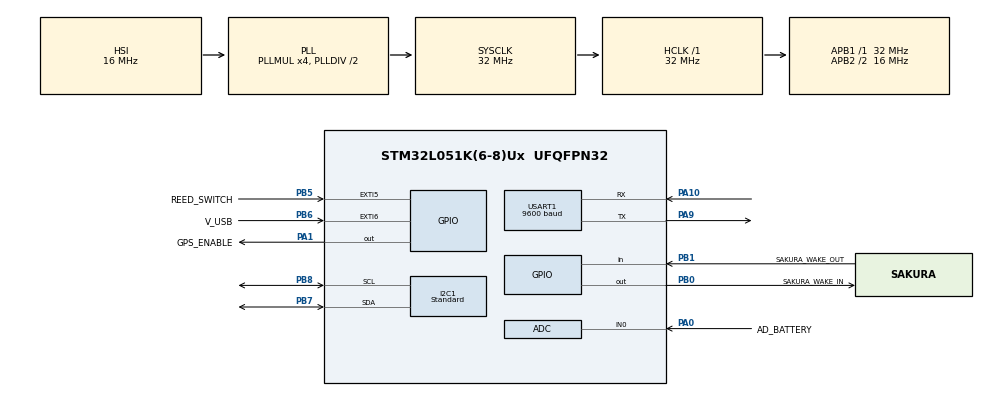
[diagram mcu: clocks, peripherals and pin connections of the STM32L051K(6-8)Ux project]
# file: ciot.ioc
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ADC.ContinuousConvMode=ENABLE
ADC.SamplingTime=ADC_SAMPLETIME_7CYCLES_5
I2C1.Analog_Filter=I2C_ANALOGFILTER_ENABLE
I2C1.I2C_Fall_Time=0
I2C1.I2C_Rise_Time=0
I2C1.I2C_Speed_Mode=I2C_Standard
I2C1.OwnAddress=0x33
I2C1.Speed=100
I2C1.Timing=0x00707CBB
Mcu.Family=STM32L0
Mcu.Name=STM32L051K(6-8)Ux
Mcu.Package=UFQFPN32
NVIC.EXTI4_15_IRQn=true\:0\:0\:false\:false\:true
NVIC.I2C1_IRQn=true\:1\:0\:true\:false\:true
PA0.GPIO_Label=AD_BATTERY
PA0.Mode=IN0
PA0.Signal=ADC_IN0
PA1.GPIO_Label=GPS_ENABLE
PA1.Signal=GPIO_Output
PA10.Mode=Asynchronous
PA10.Signal=USART1_RX
PA13.Mode=Serial_Wire
PA13.Signal=SYS_SWDIO
PA14.Mode=Serial_Wire
PA14.Signal=SYS_SWCLK
PA9.Mode=Asynchronous
PA9.Signal=USART1_TX
PB0.GPIO_Label=SAKURA_WAKE_IN
PB0.Signal=GPIO_Output
PB1.GPIO_Label=SAKURA_WAKE_OUT
PB1.GPIO_PuPd=GPIO_PULLDOWN
PB1.Signal=GPIO_Input
PB5.GPIO_Label=REED_SWITCH
PB5.GPIO_ModeDefaultEXTI=GPIO_MODE_IT_FALLING
PB5.Signal=GPXTI5
PB6.GPIO_Label=V_USB
PB6.GPIO_ModeDefaultEXTI=GPIO_MODE_IT_RISING
PB6.GPIO_PuPd=GPIO_PULLDOWN
PB6.Signal=GPXTI6
PB7.GPIO_FM7=__NULL
PB7.GPIO_PuPdOD=GPIO_NOPULL
PB7.Mode=I2C
PB7.Signal=I2C1_SDA
PB8.GPIO_FM8=__NULL
PB8.GPIO_PuPdOD=GPIO_NOPULL
PB8.Mode=I2C
PB8.Signal=I2C1_SCL
PC14-OSC32_IN.Mode=LSE-External-Oscillator
PC14-OSC32_IN.Signal=RCC_OSC32_IN
PC15-OSC32_OUT.Mode=LSE-External-Oscillator
PC15-OSC32_OUT.Signal=RCC_OSC32_OUT
ProjectManager.HeapSize=0x200
ProjectManager.StackSize=0x400
ProjectManager.TargetToolchain=SW4STM32
RCC.AHBFreq_Value=32000000
RCC.APB1Freq_Value=32000000
RCC.APB1TimFreq_Value=32000000
RCC.APB2CLKDivider=RCC_HCLK_DIV2
RCC.APB2Freq_Value=16000000
RCC.APB2TimFreq_Value=32000000
RCC.HCLKFreq_Value=32000000
RCC.HSI16_VALUE=16000000
RCC.HSI_VALUE=16000000
RCC.LptimClockSelection=RCC_LPTIM1CLKSOURCE_LSE
RCC.MSI_VALUE=2097000
RCC.PLLMUL=RCC_PLLMUL_4
RCC.RTCClockSelectionVirtual=RCC_RTCCLKSOURCE_LSE
RCC.SYSCLKFreq_VALUE=32000000
RCC.SYSCLKSource=RCC_SYSCLKSOURCE_PLLCLK
RCC.VCOOutputFreq_Value=64000000
RCC.VDD_VALUE=1.8
USART1.BaudRate=9600
USART1.VirtualMode-Asynchronous=VM_ASYNC
USART1.WordLength=WORDLENGTH_8B
VP_RTC_VS_RTC_Activate.Mode=RTC_Enabled
board=ciot

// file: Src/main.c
/**
  ******************************************************************************
  * File Name          : main.c
  * Description        : Main program body
  ******************************************************************************
  ** This notice applies to any and all portions of this file
  * that are not between comment pairs USER CODE BEGIN and
  * USER CODE END. Other portions of this file, whether
  * inserted by the user or by software development tools
  * are owned by their respective copyright owners.
  *
  * COPYRIGHT(c) 2017 STMicroelectronics
  *
  * Redistribution and use in source and binary forms, with or without modification,
  * are permitted provided that the following conditions are met:
  *   1. Redistributions of source code must retain the above copyright notice,
  *      this list of conditions and the following disclaimer.
  *   2. Redistributions in binary form must reproduce the above copyright notice,
  *      this list of conditions and the following disclaimer in the documentation
  *      and/or other materials provided with the distribution.
  *   3. Neither the name of STMicroelectronics nor the names of its contributors
  *      may be used to endorse or promote products derived from this software
  *      without specific prior written permission.
  *
  * THIS SOFTWARE IS PROVIDED BY THE COPYRIGHT HOLDERS AND CONTRIBUTORS "AS IS"
  * AND ANY EXPRESS OR IMPLIED WARRANTIES, INCLUDING, BUT NOT LIMITED TO, THE
  * IMPLIED WARRANTIES OF MERCHANTABILITY AND FITNESS FOR A PARTICULAR PURPOSE ARE
  * DISCLAIMED. IN NO EVENT SHALL THE COPYRIGHT HOLDER OR CONTRIBUTORS BE LIABLE
  * FOR ANY DIRECT, INDIRECT, INCIDENTAL, SPECIAL, EXEMPLARY, OR CONSEQUENTIAL
  * DAMAGES (INCLUDING, BUT NOT LIMITED TO, PROCUREMENT OF SUBSTITUTE GOODS OR
  * SERVICES; LOSS OF USE, DATA, OR PROFITS; OR BUSINESS INTERRUPTION) HOWEVER
  * CAUSED AND ON ANY THEORY OF LIABILITY, WHETHER IN CONTRACT, STRICT LIABILITY,
  * OR TORT (INCLUDING NEGLIGENCE OR OTHERWISE) ARISING IN ANY WAY OUT OF THE USE
  * OF THIS SOFTWARE, EVEN IF ADVISED OF THE POSSIBILITY OF SUCH DAMAGE.
  *
  ******************************************************************************
  */
#include "main.h"
#include "stm32l0xx_hal.h"

/* USER CODE BEGIN Includes */
#include "ciot.h"
/* USER CODE END Includes */

ADC_HandleTypeDef hadc;

I2C_HandleTypeDef hi2c1;

RTC_HandleTypeDef hrtc;

UART_HandleTypeDef huart1;

/* USER CODE BEGIN PV */
/* Private variables ---------------------------------------------------------*/

/* USER CODE END PV */

void SystemClock_Config(void);
static void MX_GPIO_Init(void);
static void MX_I2C1_Init(void);
static void MX_USART1_UART_Init(void);
static void MX_RTC_Init(void);
static void MX_ADC_Init(void);

/* USER CODE BEGIN PFP */
/* Private function prototypes -----------------------------------------------*/

/* USER CODE END PFP */

int main(void)
{

  /* MCU Configuration----------------------------------------------------------*/

  /* Reset of all peripherals, Initializes the Flash interface and the Systick. */
  HAL_Init();

  /* USER CODE BEGIN Init */

  /* Enable Power Control clock */
  __HAL_RCC_PWR_CLK_ENABLE();

  /* USER CODE END Init */

  /* Configure the system clock */
  SystemClock_Config();

  /* USER CODE BEGIN SysInit */

  /* Disable Prefetch Buffer */
  __HAL_FLASH_PREFETCH_BUFFER_DISABLE();

  /* Enable Ultra low power mode */
  HAL_PWREx_EnableUltraLowPower();
  /* Enable the fast wake up from Ultra low power mode */
  HAL_PWREx_EnableFastWakeUp();

  /* USER CODE END SysInit */

  /* Initialize all configured peripherals */
  MX_GPIO_Init();
  MX_I2C1_Init();
  MX_USART1_UART_Init();
  MX_RTC_Init();
  MX_ADC_Init();

  /* Infinite loop */
  /* USER CODE BEGIN WHILE */
  while (1)
  {
    ciot_main();
  /* USER CODE END WHILE */

  }

}

/** System Clock Configuration
*/
void SystemClock_Config(void)
{

  RCC_OscInitTypeDef RCC_OscInitStruct;
  RCC_ClkInitTypeDef RCC_ClkInitStruct;
  RCC_PeriphCLKInitTypeDef PeriphClkInit;

    /**Configure the main internal regulator output voltage
    */
  __HAL_PWR_VOLTAGESCALING_CONFIG(PWR_REGULATOR_VOLTAGE_SCALE1);

    /**Configure LSE Drive Capability
    */
  __HAL_RCC_LSEDRIVE_CONFIG(RCC_LSEDRIVE_LOW);

    /**Initializes the CPU, AHB and APB busses clocks
    */
  RCC_OscInitStruct.OscillatorType = RCC_OSCILLATORTYPE_HSI|RCC_OSCILLATORTYPE_LSE;
  RCC_OscInitStruct.LSEState = RCC_LSE_ON;
  RCC_OscInitStruct.HSIState = RCC_HSI_ON;
  RCC_OscInitStruct.HSICalibrationValue = 16;
  RCC_OscInitStruct.PLL.PLLState = RCC_PLL_ON;
  RCC_OscInitStruct.PLL.PLLSource = RCC_PLLSOURCE_HSI;
  RCC_OscInitStruct.PLL.PLLMUL = RCC_PLLMUL_4;
  RCC_OscInitStruct.PLL.PLLDIV = RCC_PLLDIV_2;
  if (HAL_RCC_OscConfig(&RCC_OscInitStruct) != HAL_OK)
  {
    _Error_Handler(__FILE__, __LINE__);
  }

    /**Initializes the CPU, AHB and APB busses clocks
    */
  RCC_ClkInitStruct.ClockType = RCC_CLOCKTYPE_HCLK|RCC_CLOCKTYPE_SYSCLK
                              |RCC_CLOCKTYPE_PCLK1|RCC_CLOCKTYPE_PCLK2;
  RCC_ClkInitStruct.SYSCLKSource = RCC_SYSCLKSOURCE_PLLCLK;
  RCC_ClkInitStruct.AHBCLKDivider = RCC_SYSCLK_DIV1;
  RCC_ClkInitStruct.APB1CLKDivider = RCC_HCLK_DIV1;
  RCC_ClkInitStruct.APB2CLKDivider = RCC_HCLK_DIV2;

  if (HAL_RCC_ClockConfig(&RCC_ClkInitStruct, FLASH_LATENCY_1) != HAL_OK)
  {
    _Error_Handler(__FILE__, __LINE__);
  }

  PeriphClkInit.PeriphClockSelection = RCC_PERIPHCLK_USART1|RCC_PERIPHCLK_I2C1
                              |RCC_PERIPHCLK_RTC;
  PeriphClkInit.Usart1ClockSelection = RCC_USART1CLKSOURCE_PCLK2;
  PeriphClkInit.I2c1ClockSelection = RCC_I2C1CLKSOURCE_PCLK1;
  PeriphClkInit.RTCClockSelection = RCC_RTCCLKSOURCE_LSE;
  if (HAL_RCCEx_PeriphCLKConfig(&PeriphClkInit) != HAL_OK)
  {
    _Error_Handler(__FILE__, __LINE__);
  }

    /**Configure the Systick interrupt time
    */
  HAL_SYSTICK_Config(HAL_RCC_GetHCLKFreq()/1000);

    /**Configure the Systick
    */
  HAL_SYSTICK_CLKSourceConfig(SYSTICK_CLKSOURCE_HCLK);

  /* SysTick_IRQn interrupt configuration */
  HAL_NVIC_SetPriority(SysTick_IRQn, 0, 0);
}

/* ADC init function */
static void MX_ADC_Init(void)
{

  ADC_ChannelConfTypeDef sConfig;

    /**Configure the global features of the ADC (Clock, Resolution, Data Alignment and number of conversion)
    */
  hadc.Instance = ADC1;
  hadc.Init.OversamplingMode = DISABLE;
  hadc.Init.ClockPrescaler = ADC_CLOCK_SYNC_PCLK_DIV2;
  hadc.Init.Resolution = ADC_RESOLUTION_12B;
  hadc.Init.SamplingTime = ADC_SAMPLETIME_7CYCLES_5;
  hadc.Init.ScanConvMode = ADC_SCAN_DIRECTION_FORWARD;
  hadc.Init.DataAlign = ADC_DATAALIGN_RIGHT;
  hadc.Init.ContinuousConvMode = ENABLE;
  hadc.Init.DiscontinuousConvMode = DISABLE;
  hadc.Init.ExternalTrigConvEdge = ADC_EXTERNALTRIGCONVEDGE_NONE;
  hadc.Init.ExternalTrigConv = ADC_SOFTWARE_START;
  hadc.Init.DMAContinuousRequests = DISABLE;
  hadc.Init.EOCSelection = ADC_EOC_SINGLE_CONV;
  hadc.Init.Overrun = ADC_OVR_DATA_PRESERVED;
  hadc.Init.LowPowerAutoWait = DISABLE;
  hadc.Init.LowPowerFrequencyMode = DISABLE;
  hadc.Init.LowPowerAutoPowerOff = DISABLE;
  if (HAL_ADC_Init(&hadc) != HAL_OK)
  {
    _Error_Handler(__FILE__, __LINE__);
  }

    /**Configure for the selected ADC regular channel to be converted.
    */
  sConfig.Channel = ADC_CHANNEL_0;
  sConfig.Rank = ADC_RANK_CHANNEL_NUMBER;
  if (HAL_ADC_ConfigChannel(&hadc, &sConfig) != HAL_OK)
  {
    _Error_Handler(__FILE__, __LINE__);
  }

}

/* I2C1 init function */
static void MX_I2C1_Init(void)
{

  hi2c1.Instance = I2C1;
  hi2c1.Init.Timing = 0x00707CBB;
  hi2c1.Init.OwnAddress1 = 102;
  hi2c1.Init.AddressingMode = I2C_ADDRESSINGMODE_7BIT;
  hi2c1.Init.DualAddressMode = I2C_DUALADDRESS_DISABLE;
  hi2c1.Init.OwnAddress2 = 0;
  hi2c1.Init.OwnAddress2Masks = I2C_OA2_NOMASK;
  hi2c1.Init.GeneralCallMode = I2C_GENERALCALL_DISABLE;
  hi2c1.Init.NoStretchMode = I2C_NOSTRETCH_DISABLE;
  if (HAL_I2C_Init(&hi2c1) != HAL_OK)
  {
    _Error_Handler(__FILE__, __LINE__);
  }

    /**Configure Analogue filter
    */
  if (HAL_I2CEx_ConfigAnalogFilter(&hi2c1, I2C_ANALOGFILTER_ENABLE) != HAL_OK)
  {
    _Error_Handler(__FILE__, __LINE__);
  }

    /**Configure Digital filter
    */
  if (HAL_I2CEx_ConfigDigitalFilter(&hi2c1, 0) != HAL_OK)
  {
    _Error_Handler(__FILE__, __LINE__);
  }

}

/* RTC init function */
static void MX_RTC_Init(void)
{

    /**Initialize RTC Only
    */
  hrtc.Instance = RTC;
  hrtc.Init.HourFormat = RTC_HOURFORMAT_24;
  hrtc.Init.AsynchPrediv = 127;
  hrtc.Init.SynchPrediv = 255;
  hrtc.Init.OutPut = RTC_OUTPUT_DISABLE;
  hrtc.Init.OutPutRemap = RTC_OUTPUT_REMAP_NONE;
  hrtc.Init.OutPutPolarity = RTC_OUTPUT_POLARITY_HIGH;
  hrtc.Init.OutPutType = RTC_OUTPUT_TYPE_OPENDRAIN;
  if (HAL_RTC_Init(&hrtc) != HAL_OK)
  {
    _Error_Handler(__FILE__, __LINE__);
  }

}

/* USART1 init function */
static void MX_USART1_UART_Init(void)
{

  huart1.Instance = USART1;
  huart1.Init.BaudRate = 9600;
  huart1.Init.WordLength = UART_WORDLENGTH_8B;
  huart1.Init.StopBits = UART_STOPBITS_1;
  huart1.Init.Parity = UART_PARITY_NONE;
  huart1.Init.Mode = UART_MODE_TX_RX;
  huart1.Init.HwFlowCtl = UART_HWCONTROL_NONE;
  huart1.Init.OverSampling = UART_OVERSAMPLING_16;
  huart1.Init.OneBitSampling = UART_ONE_BIT_SAMPLE_DISABLE;
  huart1.AdvancedInit.AdvFeatureInit = UART_ADVFEATURE_NO_INIT;
  if (HAL_UART_Init(&huart1) != HAL_OK)
  {
    _Error_Handler(__FILE__, __LINE__);
  }

}

/** Configure pins as
        * Analog
        * Input
        * Output
        * EVENT_OUT
        * EXTI
*/
static void MX_GPIO_Init(void)
{

  GPIO_InitTypeDef GPIO_InitStruct;

  /* GPIO Ports Clock Enable */
  __HAL_RCC_GPIOC_CLK_ENABLE();
  __HAL_RCC_GPIOA_CLK_ENABLE();
  __HAL_RCC_GPIOB_CLK_ENABLE();

  /*Configure GPIO pin Output Level */
  HAL_GPIO_WritePin(GPS_ENABLE_GPIO_Port, GPS_ENABLE_Pin, GPIO_PIN_RESET);

  /*Configure GPIO pin Output Level */
  HAL_GPIO_WritePin(SAKURA_WAKE_IN_GPIO_Port, SAKURA_WAKE_IN_Pin, GPIO_PIN_RESET);

  /*Configure GPIO pin : GPS_ENABLE_Pin */
  GPIO_InitStruct.Pin = GPS_ENABLE_Pin;
  GPIO_InitStruct.Mode = GPIO_MODE_OUTPUT_PP;
  GPIO_InitStruct.Pull = GPIO_NOPULL;
  GPIO_InitStruct.Speed = GPIO_SPEED_FREQ_LOW;
  HAL_GPIO_Init(GPS_ENABLE_GPIO_Port, &GPIO_InitStruct);

  /*Configure GPIO pin : SAKURA_WAKE_IN_Pin */
  GPIO_InitStruct.Pin = SAKURA_WAKE_IN_Pin;
  GPIO_InitStruct.Mode = GPIO_MODE_OUTPUT_PP;
  GPIO_InitStruct.Pull = GPIO_NOPULL;
  GPIO_InitStruct.Speed = GPIO_SPEED_FREQ_LOW;
  HAL_GPIO_Init(SAKURA_WAKE_IN_GPIO_Port, &GPIO_InitStruct);

  /*Configure GPIO pin : SAKURA_WAKE_OUT_Pin */
  GPIO_InitStruct.Pin = SAKURA_WAKE_OUT_Pin;
  GPIO_InitStruct.Mode = GPIO_MODE_INPUT;
  GPIO_InitStruct.Pull = GPIO_PULLDOWN;
  HAL_GPIO_Init(SAKURA_WAKE_OUT_GPIO_Port, &GPIO_InitStruct);

  /*Configure GPIO pin : REED_SWITCH_Pin */
  GPIO_InitStruct.Pin = REED_SWITCH_Pin;
  GPIO_InitStruct.Mode = GPIO_MODE_IT_FALLING;
  GPIO_InitStruct.Pull = GPIO_NOPULL;
  HAL_GPIO_Init(REED_SWITCH_GPIO_Port, &GPIO_InitStruct);

  /*Configure GPIO pin : V_USB_Pin */
  GPIO_InitStruct.Pin = V_USB_Pin;
  GPIO_InitStruct.Mode = GPIO_MODE_IT_RISING;
  GPIO_InitStruct.Pull = GPIO_PULLDOWN;
  HAL_GPIO_Init(V_USB_GPIO_Port, &GPIO_InitStruct);

  /* EXTI interrupt init*/
  HAL_NVIC_SetPriority(EXTI4_15_IRQn, 0, 0);
  HAL_NVIC_EnableIRQ(EXTI4_15_IRQn);

}

/* USER CODE BEGIN 4 */
void GPIO_Init(){
	MX_GPIO_Init();
}
/* USER CODE END 4 */

void _Error_Handler(char * file, int line)
{
  /* USER CODE BEGIN Error_Handler_Debug */
  /* User can add his own implementation to report the HAL error return state */
  NVIC_SystemReset();
  while(1)
  {
  }
  /* USER CODE END Error_Handler_Debug */
}

/************************ (C) COPYRIGHT STMicroelectronics *****END OF FILE****/
